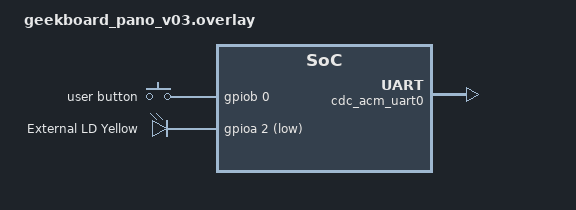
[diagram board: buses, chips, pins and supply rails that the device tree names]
// SPDX-License-Identifier: Apache-2.0

#include <zephyr/dt-bindings/input/input-event-codes.h>

/ {
	gpio_keys {
		compatible = "gpio-keys";
		user_button: button {
			label = "user button";
			gpios = <&gpiob 0 GPIO_ACTIVE_HIGH>;
			status = "okay";
			zephyr,code = <INPUT_KEY_0>;
		};
	};
	aliases {
		led1 = &ledext0;
		usrbtn = &user_button;
	};
	chosen {
		zephyr,console = &cdc_acm_uart0;
	};
};

&zephyr_udc0 {
	cdc_acm_uart0: cdc_acm_uart0 {
		compatible = "zephyr,cdc-acm-uart";
	};
};

&leds {
	ledext0: led_e0 {
		gpios = <&gpioa 2 GPIO_ACTIVE_LOW>;
		label = "External LD Yellow";
	};
};

